# DA14681 register map
Vendor: Dialog; Series: DA14681; File version: 1.2
CPU: CM0 r1p0, little endian, MPU, FPU, 3 interrupt priority bits
Registers are 16-bit, read-write, reset 0x0 unless marked. A register's access mark holds for its fields unless they carry their own. Offsets are from the block's base; [hi:lo] are bit positions; {n}, {i} and the like mark numbered series.

## AES_HASH — AES_HASH registers
Base 0x40020000
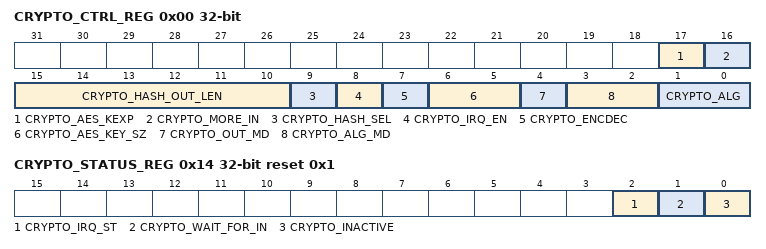
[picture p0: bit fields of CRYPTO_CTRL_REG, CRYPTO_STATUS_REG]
0x00 CRYPTO_CTRL_REG 32-bit — Crypto Control register
  [17] CRYPTO_AES_KEXP — It forces (active high) the execution of the key expansion process with the starting of the AES encryption/decryption process. The bit will be cleared automatically by the hardware, after the completion of the AES key expansion process.
  [16] CRYPTO_MORE_IN — 0 - Define that this is the last input block. When the current input is consumed by the crypto engine and the output data is written to the memory, the calculation ends (CRYPTO_INACTIVE goes to one). 1 - The current input data block is not the last. More input data will follow. When the current input is consumed, the engine stops and waits for more data (CRYPTO_WAIT_FOR_IN goes to one).
  [15:10] CRYPTO_HASH_OUT_LEN — The number of bytes minus one of the hash result which will be saved at the memory by the DMA. In relation with the selected hash algorithm the accepted values are: MD5: 0..15 -> 1-16 bytes SHA-1: 0..19 -> 1-20 bytes SHA-256: 0..31 -> 1 - 32 bytes SHA-256/224: 0..27 -> 1- 28 bytes SHA-384: 0..47 -> 1 - 48 bytes SHA-512: 0..63 -> 1 - 64 bytes SHA-512/224: 0..27 -> 1- 28 bytes SHA-512/256: 0..31 -> 1 - 32 bytes
  [9] CRYPTO_HASH_SEL — Selects the type of the algorithm 0 - The encryption algorithm (AES) 1 - A hash algorithm. The exact algorithm is defined by the fileds CRYPTO_ALG and CRYPTO_ALG_MD.
  [8] CRYPTO_IRQ_EN — Interrupt Request Enable 0 - The interrupt generation ability is disabled. 1 - The interrupt generation ability is enabled. Generates an interrupt request at the end of operation.
  [7] CRYPTO_ENCDEC — Encryption/Decryption 0 - Decryption 1 - Encryption
  [6:5] CRYPTO_AES_KEY_SZ — The size of AES Key 00 - 128 bits AES Key 01 - 192 bits AES Key 10 - 256 bits AES Key 11 - 256 bits AES Key
  [4] CRYPTO_OUT_MD — Output Mode. This field makes sense only when the AES algorithm is selected (CRYPTO_HASH_SEL =0) 0 - Write back to memory all the resulting data 1 - Write back to memory only the final block of the resulting data
  [3:2] CRYPTO_ALG_MD — It defines the mode of operation of the AES algorithm when the controller is configured for an encryption/decryption processing (CRYPTO_HASH_SEL = 0). 00 - ECB 01 - ECB 10 - CTR 11 - CBC When the controller is configured to applies a HASH function, this field selects the desired HASH algorithm with the help of the CRYPTO_ALG. 00 - HASH algorithms that are based on 32 bits operations 01 - HASH algorithms that are based on 64 bits operations 10 - Reserved 11 - Reserved See also the CRYPTO_ALG field.
  [1:0] CRYPTO_ALG — Algorithm selection. When CRYPTO_HASH_SEL = 0 the only available choice is the AES algorithm. 00 - AES 01 - Reserved 10 - Reserved 11 - Reserved When CRYPTO_HASH_SEL = 1, this field selects the desired hash algorithms, with the help of the CRYPTO_ALG_MD field. If CRYPTO_ALG_MD = 00 00 - MD5 01 - SHA-1 10 - SHA-256/224 11 - SHA-256 If CRYPTO_ALG_MD = 01 00 - SHA-384 01 - SHA-512 10 - SHA-512/224 11 - SHA-512/256
0x04 CRYPTO_START_REG 32-bit — Crypto Start calculation
  [0] CRYPTO_START wo — Write 1 to initiate the processing of the input data. This register is auto-cleared.
0x08 CRYPTO_FETCH_ADDR_REG 32-bit (reset mask 0x7FFFFFFF) — Crypto DMA fetch register
  [31:0] CRYPTO_FETCH_ADDR — The memory address from where will be retrieved the data that will be processed. The value of this register is updated as the calculation proceeds and the output data are written to the memory.
0x0C CRYPTO_LEN_REG 32-bit — Crypto Length of the input block in bytes
  [23:0] CRYPTO_LEN — It contains the number of bytes of input data. If this number is not a multiple of a block size, the data is automatically extended with zeros. The value of this register is updated as the calculation proceeds and the output data are written to the memory.
0x10 CRYPTO_DEST_ADDR_REG 32-bit (reset mask 0x7FFFFFFF) — Crypto DMA destination memory
  [31:0] CRYPTO_DEST_ADDR — Destination address at where the result of the processing is stored. The value of this register is updated as the calculation proceeds and the output data are written to the memory.
0x14 CRYPTO_STATUS_REG 32-bit reset 0x1 — Crypto Status register
  [2] CRYPTO_IRQ_ST ro — The status of the interrupt request line of the CRYPTO block. 0 - There is no active interrupt request. 1 - An interrupt request is pending.
  [1] CRYPTO_WAIT_FOR_IN ro — Indicates the situation where the engine waits for more input data. This is applicable when the CRYPTO_MORE_IN= 1, so the input data are fragmented in the memory. 0 - The crypto is not waiting for more input data. 1 - The crypto waits for more input data. The CRYPTO_INACTIVE flag remains to zero to indicate that the calculation is not finished. The supervisor of the CRYPTO must program to the CRYPTO_FETCH_ADDR and CRYPTO_LEN a new input data fragment. The calculation will be continued as soon as the CRYPTO_START register will be written with 1. This action will clear the CRYPTO_WAIT_FOR_IN flag.
  [0] CRYPTO_INACTIVE ro — 0 - The CRYPTO is active. The processing is in progress. 1 - The CRYPTO is inactive. The processing has finished.
0x18 CRYPTO_CLRIRQ_REG 32-bit — Crypto Clear interrupt request
  [0] CRYPTO_CLRIRQ wo — Write 1 to clear a pending interrupt request.
0x1C CRYPTO_MREG0_REG 32-bit (reset mask 0x7FFFFFFF) — Crypto Mode depended register 0
  [31:0] CRYPTO_MREG0 — It contains information that are depended by the mode of operation, when is used the AES algorithm: CBC - IV[31:0] CTR - CTRBLK[31:0]. It is the initial value of the 32 bits counter. At any other mode, the contents of this register has no meaning.
{0x1C+4i} CRYPTO_MREG{i}_REG 32-bit (reset mask 0x7FFFFFFF) (i=1..3) — Crypto Mode depended register {i}
  [31:0] CRYPTO_MREG{i} — It contains information that are depended by the mode of operation, when is used the AES algorithm: CBC - IV[{32i+31}:{32i}] CTR - CTRBLK[{32i+31}:{32i}] At any other mode, the contents of this register has no meaning.
0x100 CRYPTO_KEYS_START 32-bit (reset mask 0x7FFFFFFF) — Crypto First position of the AES keys storage memory
  [31:0] CRYPTO_KEY_X wo — CRYPTO_KEY_(0-63) This is the AES keys storage memory. This memory is accessible via AHB slave interface, only when the CRYPTO is inactive (CRYPTO_INACTIVE = 1).

## Notices in the file
Copyright (C) 2018 Dialog Semiconductor.
This computer program includes Confidential, Proprietary Information
of Dialog Semiconductor. All Rights Reserved.
